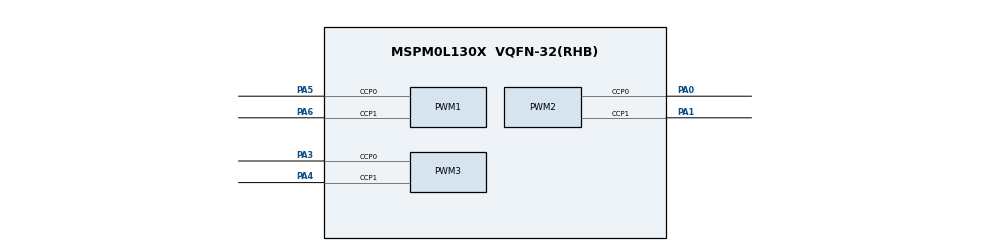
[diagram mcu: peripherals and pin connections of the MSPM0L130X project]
/**
 * @cliArgs --device "MSPM0L130X" --part "Default" --package "VQFN-32(RHB)" --product "mspm0_sdk@2.04.00.06"
 * @versions {"tool":"1.23.0+4000"}
 */

/**
 * Import the modules used in this configuration.
 */
const Board  = scripting.addModule("/ti/driverlib/Board");
const PWM    = scripting.addModule("/ti/driverlib/PWM", {}, false);
const PWM1   = PWM.addInstance();
const PWM2   = PWM.addInstance();
const PWM3   = PWM.addInstance();
const SYSCTL = scripting.addModule("/ti/driverlib/SYSCTL");

/**
 * Write custom configuration values to the imported modules.
 */
Board.peripheral.$assign = "DEBUGSS";

PWM1.$name                          = "PWM_0";
PWM1.timerCount                     = 2000;
PWM1.pwmMode                        = "EDGE_ALIGN_UP";
PWM1.timerStartTimer                = true;
PWM1.peripheral.ccp0Pin.$assign     = "PA5";
PWM1.peripheral.ccp1Pin.$assign     = "PA6";
PWM1.PWM_CHANNEL_0.$name            = "ti_driverlib_pwm_PWMTimerCC0";
PWM1.PWM_CHANNEL_0.ccValue          = 999;
PWM1.PWM_CHANNEL_1.$name            = "ti_driverlib_pwm_PWMTimerCC1";
PWM1.ccp0PinConfig.$name            = "ti_driverlib_gpio_GPIOPinGeneric0";
PWM1.ccp0PinConfig.enableConfig     = true;
PWM1.ccp0PinConfig.internalResistor = "PULL_DOWN";
PWM1.ccp1PinConfig.$name            = "ti_driverlib_gpio_GPIOPinGeneric1";
PWM1.ccp1PinConfig.enableConfig     = true;
PWM1.ccp1PinConfig.internalResistor = "PULL_DOWN";

PWM2.$name                      = "PWM_1";
PWM2.timerCount                 = 2000;
PWM2.timerStartTimer            = true;
PWM2.pwmMode                    = "EDGE_ALIGN_UP";
PWM2.peripheral.ccp0Pin.$assign = "PA0";
PWM2.peripheral.ccp1Pin.$assign = "PA1";
PWM2.PWM_CHANNEL_0.$name        = "ti_driverlib_pwm_PWMTimerCC2";
PWM2.PWM_CHANNEL_0.ccValue      = 999;
PWM2.PWM_CHANNEL_1.$name        = "ti_driverlib_pwm_PWMTimerCC3";
PWM2.PWM_CHANNEL_1.ccValue      = 999;
PWM2.ccp0PinConfig.$name        = "ti_driverlib_gpio_GPIOPinGeneric2";
PWM2.ccp0PinConfig.enableConfig = true;
PWM2.ccp1PinConfig.$name        = "ti_driverlib_gpio_GPIOPinGeneric3";
PWM2.ccp1PinConfig.enableConfig = true;

PWM3.$name                      = "PWM_2";
PWM3.timerCount                 = 2000;
PWM3.pwmMode                    = "EDGE_ALIGN_UP";
PWM3.timerStartTimer            = true;
PWM3.peripheral.ccp0Pin.$assign = "PA3";
PWM3.peripheral.ccp1Pin.$assign = "PA4";
PWM3.PWM_CHANNEL_0.$name        = "ti_driverlib_pwm_PWMTimerCC4";
PWM3.PWM_CHANNEL_0.ccValue      = 999;
PWM3.PWM_CHANNEL_1.$name        = "ti_driverlib_pwm_PWMTimerCC5";
PWM3.PWM_CHANNEL_1.ccValue      = 999;
PWM3.ccp0PinConfig.$name        = "ti_driverlib_gpio_GPIOPinGeneric4";
PWM3.ccp0PinConfig.enableConfig = true;
PWM3.ccp1PinConfig.$name        = "ti_driverlib_gpio_GPIOPinGeneric5";
PWM3.ccp1PinConfig.enableConfig = true;


/**
 * Pinmux solution for unlocked pins/peripherals. This ensures that minor changes to the automatic solver in a future
 * version of the tool will not impact the pinmux you originally saw.  These lines can be completely deleted in order to
 * re-solve from scratch.
 */
Board.peripheral.swclkPin.$suggestSolution = "PA20";
Board.peripheral.swdioPin.$suggestSolution = "PA19";
PWM1.peripheral.$suggestSolution           = "TIMG0";
PWM2.peripheral.$suggestSolution           = "TIMG1";
PWM3.peripheral.$suggestSolution           = "TIMG2";
SYSCTL.peripheral.$suggestSolution         = "SYSCTL";
